# AE722F80F55D5AS_CM55_HE_View register map
Vendor: Alif Semiconductor; Series: E7; File version: 1.0
CPU: CM55 r1p0, selectable endian, MPU, FPU, double-precision FPU, DSP, VTOR, 8 interrupt priority bits, 1 SAU regions
Registers are 32-bit, read-write, reset 0x0 unless marked. A register's access mark holds for its fields unless they carry their own. Offsets are from the block's base; [hi:lo] are bit positions; lines under a group give offsets from that group; {n}, {i} and the like mark numbered series; 'fields as' and 'values as' point back to an identical list.

## MHU_A32_M55HE_0_RX
Base 0x40000000
Same registers: MHU_A32_M55HE_1_RX 0x40020000, MHU_SECPU_M55HE_0_RX 0x40040000, MHU_SECPU_M55HE_1_RX 0x40060000, MHU_M55HP_M55HE_0_RX 0x40080000, MHU_M55HP_M55HE_1_RX 0x400A0000
{0x0+0x20*i} MHU_RX_CHANNEL_CFG[{i}] (i=0..1) group
  0x00 MHU_CH_ST ro — Channel (n) Status Register
    [31:0] FLAG_x — Channel flag status Each bit can be used as individual flag or bits can be grouped. The usage depends upon the transport protocol used. Bits in this register are set by writing 1 to the corresponding bit in the MHU_CHn_SET register. Bits in this register are cleared by writing 1 to the corresponding bit the MHU_CHn_CLRregister. If software: - Sets a bit that is already set, the bit remains set. - Clears a bit that is already cleared, the bit remains cleared. - Sets and clears a bit at the same time, the bit remains set. It is strongly recommended that software follows the transport protocols defined in Section MHU Functional Description.
  0x04 MHU_CH_ST_MSK ro — Channel (n) Status Masked Register
    [31:0] FLAG_MSK_x — Channel flag status after the mask is applied. When this field is nonzero, the interrupt for the channel is asserted. The value (VALUE) in this register is: Value = MHU_CHn_ST & ( ~MHU_CHn_MSK_ST), at the point theread occurs.
  0x08 MHU_CH_CLR wo — Channel Clear Register
    [31:0] FLAG_CLR_x — Channel flag clear Write 1 to a bit clears the corresponding bit in the MHU_CHn_ST and MHU_CHn_ST_MSK. Writing 0 has no effect. Each bit always reads as 0.
  0x10 MHU_CH_MSK_ST ro — Channel (n) Mask Status Register
    [31:0] FLAG_MSK_x — Channel flag mask When a bit is unmasked, the corresponding bits in the MHU_CHn_ST and MHU_CHn_ST_MSKregisters have the same value. When a bit is masked, the corresponding bit in the MHU_CHn_ST_MSK register alwaysreads as 0.
      0=Flag bit is unmasked; 1=Flag bit is masked
  0x14 MHU_CH_MSK_SET wo — Channel (n) Mask Set Register
    [31:0] FLAG_MSK_SET_x — Channel flag mask set Writing 1 to a bit sets the corresponding bit in the MHU_CHn_MSK_ST register. Writing 0 has no effect. Each bit always reads as 0.
  0x18 MHU_CH_MSK_CLR wo — Channel (n) Mask Clear Register
    [31:0] FLAG_MSK_CLR_x — Channel flag mask clear Write 1 to a bit clears the corresponding bit in the MHU_CHn_MSK_ST register. Writing 0 has no effect. Each bit always reads as 0.
0xF80 MHU_CFG reset 0x2 — Module Configuration Register
  [6:0] CFG_DEF ro — Number of channels
    2=2 channels
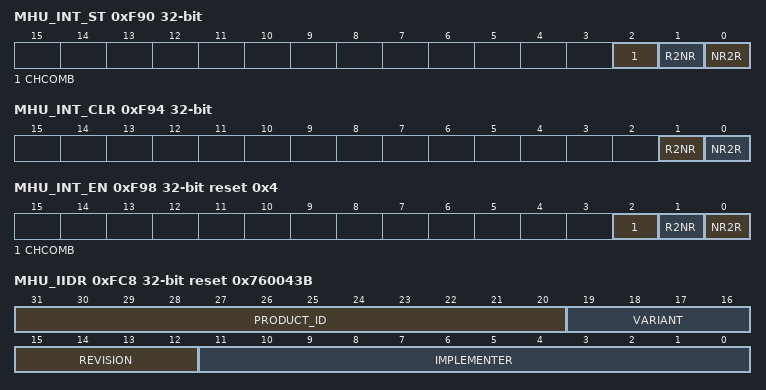
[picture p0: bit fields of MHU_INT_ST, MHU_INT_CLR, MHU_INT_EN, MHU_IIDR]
0xF90 MHU_INT_ST ro — Interrupt Status Register
  [2] CHCOMB — Channel Combined interrupt status There is no corresponding bit in the MHU_INT_CLR register. To clear this interrupt, softwaremust clear the underlying interrupt.
    0=No interrupt has occurred on any channel; 1=An interrupt has occurred on at least one channel
  [1] R2NR — Ready to Not Ready interrupt status
    0=Ready to Not Ready interrupt has not occurred; 1=Ready to Not Ready interrupt has occurred
  [0] NR2R — Not Ready to Ready interrupt status
    0=Not Ready to Ready interrupt has not occurred; 1=Not Ready to Ready interrupt has occurred
0xF94 MHU_INT_CLR wo — Interrupt Clear Register
  [1] R2NR — Clear Ready to Not Ready interrupt Write 1 to clear the interrupt. Writing 0 has no effect.
  [0] NR2R — Clear Not Ready to Ready interrupt Write 1 to clear the interrupt. Writing 0 has no effect.
0xF98 MHU_INT_EN reset 0x4 — Interrupt Enable Register
  [2] CHCOMB — Channel Combined interrupt enable
    0=Combined interrupt is disabled; 1=Combined interrupt is enabled
  [1] R2NR — Ready to Not Ready interrupt enable
    0=Disables the generation of Ready to Not Ready interrupt; 1=Enables the generation of Ready to Not Ready interrupt
  [0] NR2R — Not Ready to Ready interrupt enable
    0=Disables the generation of Not Ready to Ready interrupt; 1=Enables the generation of Not Ready to Ready interrupt
{0xFA0+4i} MHU_CHCOMB_INT_ST{i} ro (i=0..2) — Channel Combined Interrupt Status Register for Channels {32i}-{32i+31}
  [31:0] CH_INT_ST_x — Interrupt status for {32i}-{32i+31} channels Each bit indicates whether a channel has a pending interrupt or not. A bit relating to an unimplemented channel is Reserved and treated as RAZ/WI.
0xFAC MHU_CHCOMB_INT_ST3 ro — Channel Combined Interrupt Status Register for Channels 96-123
  [27:0] CH_INT_ST_x — Interrupt status for 96-123 channels Each bit indicates whether a channel has a pending interrupt or not. A bit relating to an unimplemented channel is Reserved and treated as RAZ/WI.
0xFC8 MHU_IIDR ro reset 0x760043B — Implementer Identification Register
  [31:20] PRODUCT_ID — MHU part ID
  [19:16] VARIANT — Major revision of the MHU
  [15:12] REVISION — Minor revisions of the MHU
  [11:0] IMPLEMENTER — Contains the JEP106 code: [11-8] JEP106 continuation code of implementer [7] Always 0 [6-0] JEP106 identity code of implementer
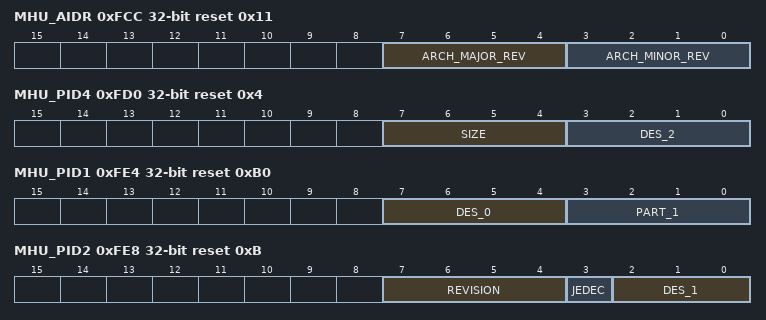
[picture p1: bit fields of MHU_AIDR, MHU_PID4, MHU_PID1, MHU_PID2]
0xFCC MHU_AIDR ro reset 0x11 — Architecture Identification Register
  [7:4] ARCH_MAJOR_REV — MHU architecture major revision Others: Reserved
    1=MHUv2
  [3:0] ARCH_MINOR_REV — MHU architecture minor revision Others: Reserved
    0=Minor revision 0; 1=Minor revision 1
0xFD0 MHU_PID4 ro reset 0x4 — Peripheral ID 4 Register
  [7:4] SIZE — Number of 4KB occupied by the System ID block. This field is deprecated.
  [3:0] DES_2 — JEP continuation
0xFE0 MHU_PID0 ro reset 0x76 — Peripheral ID 0 Register
  [7:0] PART_0 — Bits [7:0] of part ID.
0xFE4 MHU_PID1 ro reset 0xB0 — Peripheral ID 1 Register
  [7:4] DES_0 — Bits [3:0] of JEP 106 identity.
  [3:0] PART_1 — Bits [11:8] of part ID.
0xFE8 MHU_PID2 ro reset 0xB — Peripheral ID 2 Register
  [7:4] REVISION — Major revision of the System ID block.
  [3] JEDEC — Indicates the use of JEDEC JEP106 identification scheme.
  [2:0] DES_1 — Bits [6:4] of JEP 106 identity.
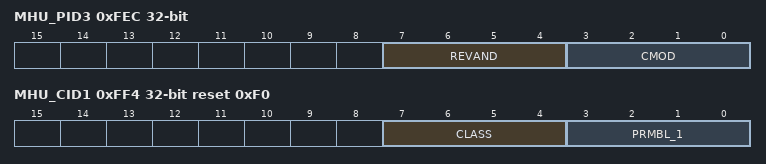
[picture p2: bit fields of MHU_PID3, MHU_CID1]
0xFEC MHU_PID3 ro — Peripheral ID 3 Register
  [7:4] REVAND — Minor revision of the System ID block.
  [3:0] CMOD — Customer modification field.
0xFF0 MHU_CID0 ro reset 0xD — Component ID 0 Register
  [7:0] PRMBL_0 — Preamble 0
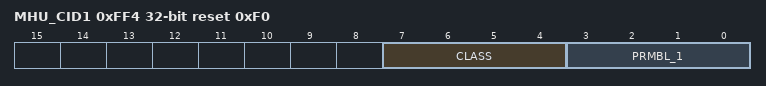
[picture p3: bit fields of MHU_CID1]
0xFF4 MHU_CID1 ro reset 0xF0 — Component ID 1 Register
  [7:4] CLASS — Class of the component.
  [3:0] PRMBL_1 — Preamble 1
0xFF8 MHU_CID2 ro reset 0x5 — Component ID 2 Register
  [7:0] PRMBL_2 — Preamble 2
0xFFC MHU_CID3 ro reset 0xB1 — Component ID 3 Register
  [7:0] PRMBL_3 — Preamble 3

## MHU_M55HE_A32_0_TX
Base 0x40010000
Same registers: MHU_M55HE_A32_1_TX 0x40030000, MHU_M55HE_SECPU_0_TX 0x40050000, MHU_M55HE_SECPU_1_TX 0x40070000, MHU_M55HE_M55HP_0_TX 0x40090000, MHU_M55HE_M55HP_1_TX 0x400B0000
Registers as MHU_A32_M55HE_0_RX, without MHU_RX_CHANNEL_CFG[*]; these are added or differ:
{0x0+0x20*i} MHU_TX_CHANNEL_CFG[{i}] (i=0..1) group
  0x00 MHU_CH_ST ro — Channel (n) Status Register
    fields as MHU_A32_M55HE_0_RX.MHU_RX_CHANNEL_CFG[0].MHU_CH_ST
  0x0C MHU_CH_SET wo — Channel (n) Set Register
    [31:0] FLAG_SET_x — Channel flag set Write 1 to a bit sets the corresponding bit in the MHU_CHn_ST. Writing 0 has no effect. Each bit always reads as 0.
  0x10 MHU_CH_INT_ST ro — Channel (n) Interrupt Status Register
    [0] CH_CLR — Channel Clear Interrupt status bit CH_CLR bit is: Set to 1 when the Receiver writes to MHU_CHn_CLR registers. Note: If the Sender domain is not powered on, or is held in reset at the point the write occurs, then there is no requirement for the field to be set to 1. Set to 0 when the Sender writes 1 to the MHU_CHn_INT_CLR[CH_CLR] bit. Setting MHU_CHn_INT_ST [CH_CLR] bit to 1 takes priority of setting the bit to 0. The value of the MHU_CHn_INT_EN[CH_CLR] bit has no effect on the value of MHU_CHn_INT_ST register.
      0=No Channel Clear interrupt has occurred; 1=A Channel Clear interrupt has occurred
  0x14 MHU_CH_INT_CLR wo — Channel (n) Interrupt Clear Register
    [0] CH_CLR — Clears MHU_CHn_INT_ST[CH_CLR] bit. Write 1 to clear the interrupt. Writing 0 has no effect. This field always reads as 0.
  0x18 MHU_CH_INT_EN — Channel (n) Interrupt Enable Register
    [0] CH_CLR — Channel Clear interrupt enable
      0=Channel Clear interrupt disabled; 1=Channel Clear interrupt enabled
0xF80 MHU_CFG ro reset 0x2 — Module Configuration Register
  [6:0] CFG_DEF — Number of channels
    2=2 channels
0xF84 MHU_RESP_CFG — Response Configuration Register
  [0] NR_RESP — Response generated when the Sender attempts to access any register of a channel, when MHU_ACCESS_REQUEST[ACC_REQ] bit is 0.
    0=Access is treated as RAZ/WI with no error generated; 1=Access is treated as RAZ/WI and an error is generated
0xF88 MHU_ACCESS_REQUEST — Access Request Register
  [0] ACC_REQ — Access Request
    0=Receiver is not requested to be ready to receive transfer; 1=Receiver is requested to be ready to receive transfer
0xF8C MHU_ACCESS_READY — Access Ready Register
  [0] ACC_RDY — Access Ready
    0=Receiver is not ready to receive transfer; 1=Receiver is ready to receive transfer
0xFF4 MHU_CID1 ro reset 0xF0 — Component ID 1 Register
  [7:4] CLASS — Class of the component
  [3:0] PRMBL_1 — Preamble 1
